# DSPIC33FJ12MC201 register map
Vendor: Microchip
Registers are 16-bit, read-write, reset 0x0 unless marked. A register's access mark holds for its fields unless they carry their own. Addresses are absolute, and some are shared; only a register's first bit layout is shown; [hi:lo] are bit positions; {n}, {i} and the like mark numbered series; 'fields as' and 'values as' point back to an identical list.

## SFR
{0x0+2i} WREG{i} (i=0..14)
0x1E WREG15 reset 0x800
0x20 SPLIM
0x22 ACCAL reset not defined — (power-on value xxxxxxxxxxxxxxxx)
0x24 ACCAH reset not defined — (power-on value xxxxxxxxxxxxxxxx)
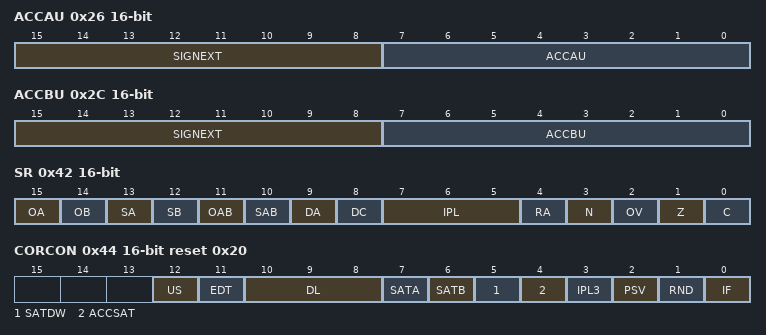
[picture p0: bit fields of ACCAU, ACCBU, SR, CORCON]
0x26 ACCAU reset not defined — (power-on value 00000000xxxxxxxx)
  [15:8] SIGNEXT ro, [7:0] ACCAU
0x28 ACCBL reset not defined — (power-on value xxxxxxxxxxxxxxxx)
0x2A ACCBH reset not defined — (power-on value xxxxxxxxxxxxxxxx)
0x2C ACCBU reset not defined — (power-on value 00000000xxxxxxxx)
  [15:8] SIGNEXT ro, [7:0] ACCBU
0x2E PCL ro
0x30 PCH ro
  [7:0] PCH
0x32 TBLPAG
  [7:0] TBLPAG
0x34 PSVPAG
  [7:0] PSVPAG
0x36 RCOUNT reset not defined — (power-on value --xxxxxxxxxxxxxx)
  [13:0] RCOUNT
0x38 DCOUNT reset not defined — (power-on value --xxxxxxxxxxxxxx)
  [13:0] DCOUNT
0x3A DOSTARTL reset not defined — (power-on value xxxxxxxxxxxxxxx0)
0x3C DOSTARTH reset not defined — (power-on value ----------xxxxxx)
  [5:0] DOSTARTH
0x3E DOENDL reset not defined — (power-on value xxxxxxxxxxxxxxx0)
0x40 DOENDH reset not defined — (power-on value ----------xxxxxx)
  [5:0] DOENDH
0x42 SR
  [15] OA ro
  [14] OB ro
  [13] SA — (can only be cleared)
  [12] SB — (can only be cleared)
  [11] OAB ro
  [10] SAB — (can only be cleared)
  [9] DA ro
  [8] DC
  [7:5] IPL
  [4] RA ro
  [3] N
  [2] OV
  [1] Z
  [0] C
0x44 CORCON reset 0x20
  [12] US
  [11] EDT wo
  [10:8] DL ro
  [7] SATA
  [6] SATB
  [5] SATDW
  [4] ACCSAT
  [3] IPL3 — (can only be cleared)
  [2] PSV
  [1] RND
  [0] IF
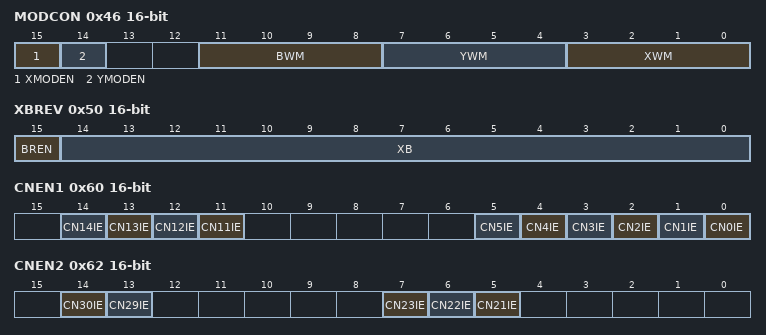
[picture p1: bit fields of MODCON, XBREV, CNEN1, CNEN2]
0x46 MODCON
  [15] XMODEN, [14] YMODEN, [11:8] BWM, [7:4] YWM, [3:0] XWM
0x48 XMODSRT reset not defined — (power-on value xxxxxxxxxxxxxxx0)
  [15:0] XS
0x4A XMODEND reset not defined — (power-on value xxxxxxxxxxxxxxx1)
  [15:0] XE
0x4C YMODSRT reset not defined — (power-on value xxxxxxxxxxxxxxx0)
  [15:0] YS
0x4E YMODEND reset not defined — (power-on value xxxxxxxxxxxxxxx1)
  [15:0] YE
0x50 XBREV reset not defined — (power-on value 0xxxxxxxxxxxxxxx)
  [15] BREN, [14:0] XB
0x52 DISICNT reset not defined — (power-on value --xxxxxxxxxxxxxx)
  [13:0] DISICNT
0x60 CNEN1
  [n] CN{n}IE (n=11..14), [n] CN{n}IE (n=0..5)
0x62 CNEN2
  [14] CN30IE, [13] CN29IE, [7] CN23IE, [6] CN22IE, [5] CN21IE
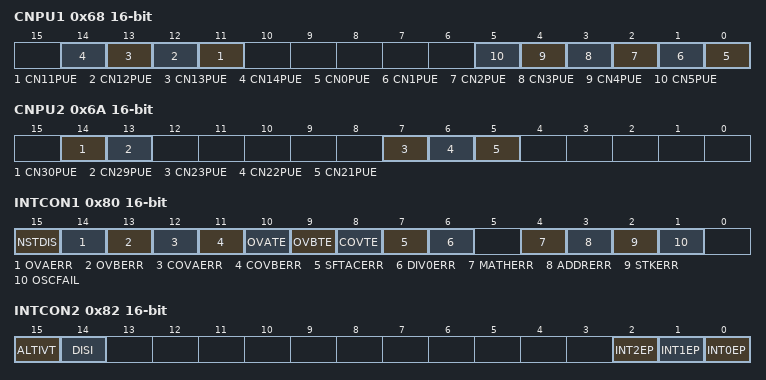
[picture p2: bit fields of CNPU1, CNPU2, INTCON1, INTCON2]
0x68 CNPU1
  [n] CN{n}PUE (n=11..14), [n] CN{n}PUE (n=0..5)
0x6A CNPU2
  [14] CN30PUE, [13] CN29PUE, [7] CN23PUE, [6] CN22PUE, [5] CN21PUE
0x80 INTCON1
  [15] NSTDIS, [14] OVAERR ro, [13] OVBERR ro, [12] COVAERR ro, [11] COVBERR ro, [10] OVATE, [9] OVBTE, [8] COVTE, [7] SFTACERR ro, [6] DIV0ERR ro, [4] MATHERR, [3] ADDRERR, [2] STKERR, [1] OSCFAIL
0x82 INTCON2
  [15] ALTIVT, [14] DISI ro, [2] INT2EP, [1] INT1EP, [0] INT0EP
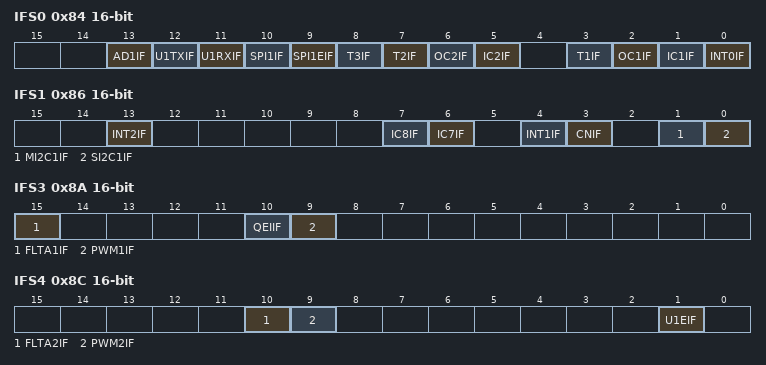
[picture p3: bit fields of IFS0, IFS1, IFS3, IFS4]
0x84 IFS0
  [13] AD1IF, [12] U1TXIF, [11] U1RXIF, [10] SPI1IF, [9] SPI1EIF, [8] T3IF, [7] T2IF, [6] OC2IF, [5] IC2IF, [3] T1IF, [2] OC1IF, [1] IC1IF, [0] INT0IF
0x86 IFS1
  [13] INT2IF, [7] IC8IF, [6] IC7IF, [4] INT1IF, [3] CNIF, [1] MI2C1IF, [0] SI2C1IF
0x8A IFS3
  [15] FLTA1IF, [10] QEIIF, [9] PWM1IF
0x8C IFS4
  [10] FLTA2IF, [9] PWM2IF, [1] U1EIF
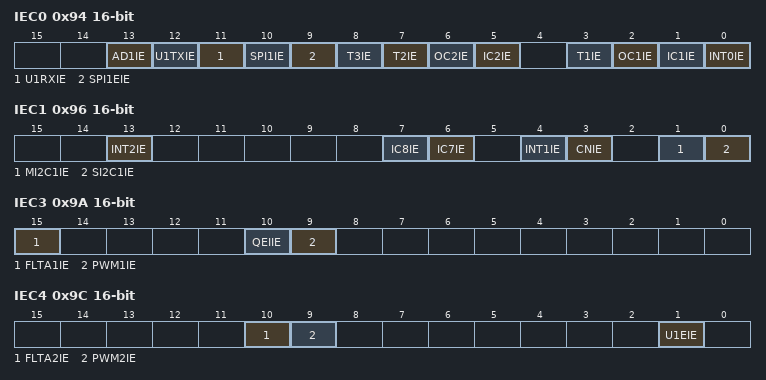
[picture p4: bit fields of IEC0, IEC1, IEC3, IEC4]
0x94 IEC0
  [13] AD1IE, [12] U1TXIE, [11] U1RXIE, [10] SPI1IE, [9] SPI1EIE, [8] T3IE, [7] T2IE, [6] OC2IE, [5] IC2IE, [3] T1IE, [2] OC1IE, [1] IC1IE, [0] INT0IE
0x96 IEC1
  [13] INT2IE, [7] IC8IE, [6] IC7IE, [4] INT1IE, [3] CNIE, [1] MI2C1IE, [0] SI2C1IE
0x9A IEC3
  [15] FLTA1IE, [10] QEIIE, [9] PWM1IE
0x9C IEC4
  [10] FLTA2IE, [9] PWM2IE, [1] U1EIE
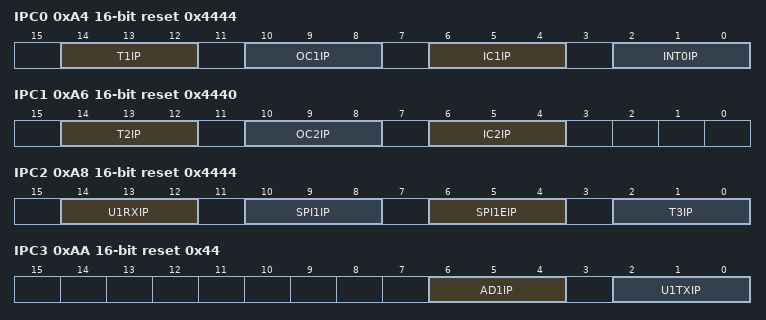
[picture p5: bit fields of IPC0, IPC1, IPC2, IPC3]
0xA4 IPC0 reset 0x4444
  [14:12] T1IP, [10:8] OC1IP, [6:4] IC1IP, [2:0] INT0IP
0xA6 IPC1 reset 0x4440
  [14:12] T2IP, [10:8] OC2IP, [6:4] IC2IP
0xA8 IPC2 reset 0x4444
  [14:12] U1RXIP, [10:8] SPI1IP, [6:4] SPI1EIP, [2:0] T3IP
0xAA IPC3 reset 0x44
  [6:4] AD1IP, [2:0] U1TXIP
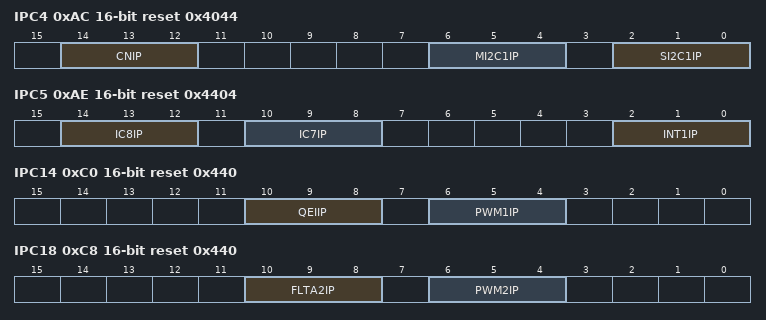
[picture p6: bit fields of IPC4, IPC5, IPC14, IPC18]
0xAC IPC4 reset 0x4044
  [14:12] CNIP, [6:4] MI2C1IP, [2:0] SI2C1IP
0xAE IPC5 reset 0x4404
  [14:12] IC8IP, [10:8] IC7IP, [2:0] INT1IP
0xB2 IPC7 reset 0x40
  [6:4] INT2IP
0xC0 IPC14 reset 0x440
  [10:8] QEIIP, [6:4] PWM1IP
0xC2 IPC15 reset 0x4000
  [14:12] FLTA1IP
0xC4 IPC16 reset 0x40
  [6:4] U1EIP
0xC8 IPC18 reset 0x440
  [10:8] FLTA2IP, [6:4] PWM2IP
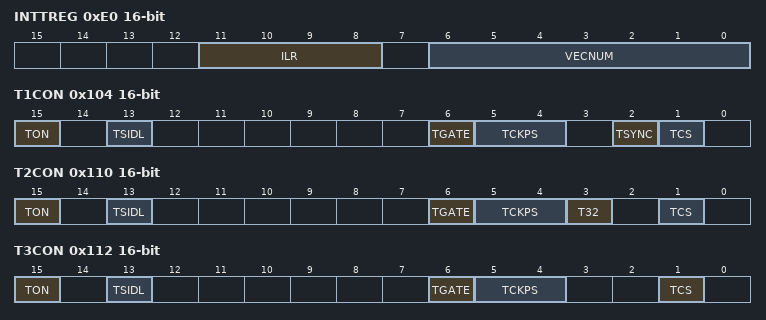
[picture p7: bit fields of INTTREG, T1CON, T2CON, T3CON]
0xE0 INTTREG
  [11:8] ILR ro, [6:0] VECNUM
0x100 TMR1 reset not defined — (power-on value xxxxxxxxxxxxxxxx)
0x102 PR1 reset 0xFFFF
0x104 T1CON
  [15] TON, [13] TSIDL, [6] TGATE, [5:4] TCKPS, [2] TSYNC, [1] TCS
0x106 TMR2 reset not defined — (power-on value xxxxxxxxxxxxxxxx)
0x108 TMR3HLD reset not defined — (power-on value xxxxxxxxxxxxxxxx)
0x10A TMR3 reset not defined — (power-on value xxxxxxxxxxxxxxxx)
0x10C PR2 reset 0xFFFF
0x10E PR3 reset 0xFFFF
0x110 T2CON
  [15] TON, [13] TSIDL, [6] TGATE, [5:4] TCKPS, [3] T32, [1] TCS
0x112 T3CON
  [15] TON, [13] TSIDL, [6] TGATE, [5:4] TCKPS, [1] TCS
0x140 IC1BUF ro reset not defined — (power-on value xxxxxxxxxxxxxxxx)
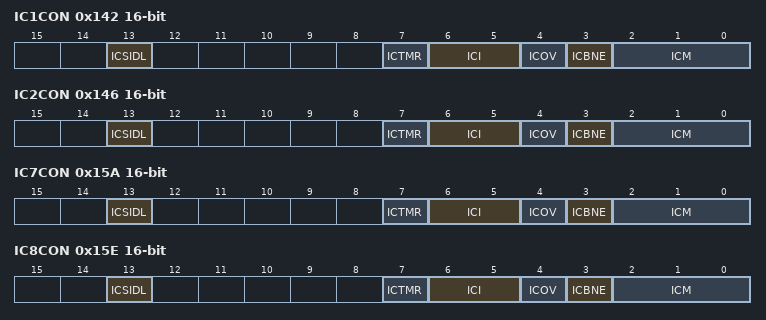
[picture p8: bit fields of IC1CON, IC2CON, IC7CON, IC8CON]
0x142 IC1CON
  [13] ICSIDL, [7] ICTMR, [6:5] ICI, [4] ICOV ro, [3] ICBNE ro, [2:0] ICM
0x144 IC2BUF ro reset not defined — (power-on value xxxxxxxxxxxxxxxx)
0x146 IC2CON
  fields as IC1CON
0x158 IC7BUF ro reset not defined — (power-on value xxxxxxxxxxxxxxxx)
0x15A IC7CON
  fields as IC1CON
0x15C IC8BUF ro reset not defined — (power-on value xxxxxxxxxxxxxxxx)
0x15E IC8CON
  fields as IC1CON
0x180 OC1RS reset not defined — (power-on value xxxxxxxxxxxxxxxx)
0x182 OC1R reset not defined — (power-on value xxxxxxxxxxxxxxxx)
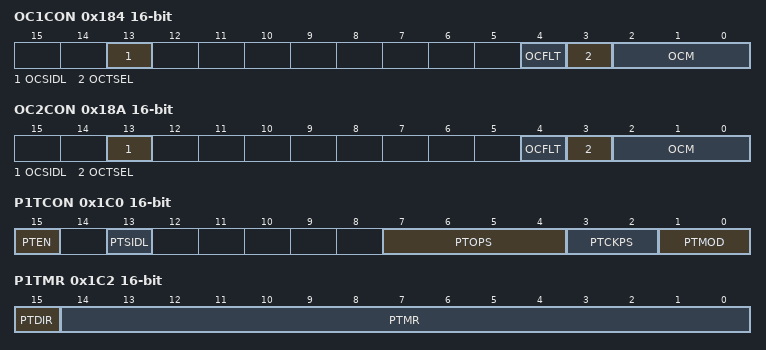
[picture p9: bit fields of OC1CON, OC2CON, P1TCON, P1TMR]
0x184 OC1CON
  [13] OCSIDL, [4] OCFLT ro, [3] OCTSEL, [2:0] OCM
0x186 OC2RS reset not defined — (power-on value xxxxxxxxxxxxxxxx)
0x188 OC2R reset not defined — (power-on value xxxxxxxxxxxxxxxx)
0x18A OC2CON
  [13] OCSIDL, [4] OCFLT ro, [3] OCTSEL, [2:0] OCM
0x1C0 P1TCON reset not defined — (power-on value 0-0-----xxxxxxxx)
  [15] PTEN, [13] PTSIDL, [7:4] PTOPS, [3:2] PTCKPS, [1:0] PTMOD
0x1C2 P1TMR
  [15] PTDIR ro, [14:0] PTMR
0x1C4 P1TPER
  [14:0] PTPER
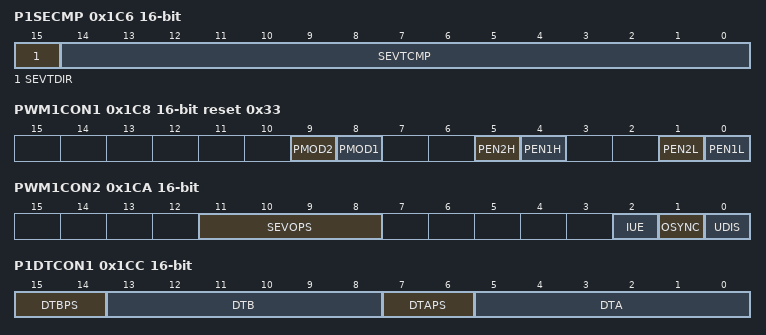
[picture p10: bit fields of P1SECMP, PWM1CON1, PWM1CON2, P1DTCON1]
0x1C6 P1SECMP
  [15] SEVTDIR, [14:0] SEVTCMP
0x1C8 PWM1CON1 reset 0x33
  [9] PMOD2, [8] PMOD1, [5] PEN2H, [4] PEN1H, [1] PEN2L, [0] PEN1L
0x1CA PWM1CON2
  [11:8] SEVOPS, [2] IUE, [1] OSYNC, [0] UDIS
0x1CC P1DTCON1
  [15:14] DTBPS, [13:8] DTB, [7:6] DTAPS, [5:0] DTA
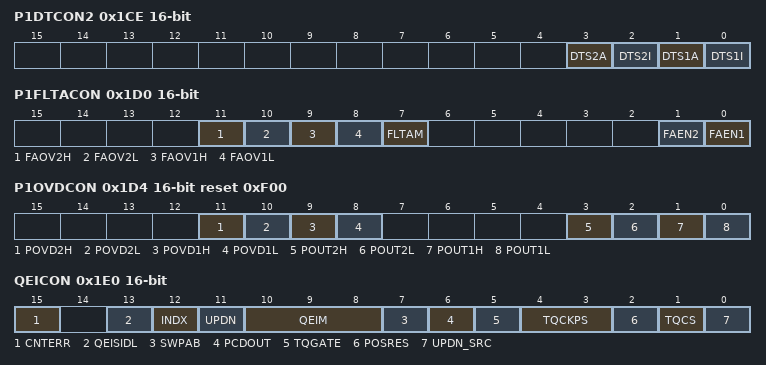
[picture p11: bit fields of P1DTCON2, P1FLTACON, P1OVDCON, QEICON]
0x1CE P1DTCON2
  [3] DTS2A, [2] DTS2I, [1] DTS1A, [0] DTS1I
0x1D0 P1FLTACON
  [11] FAOV2H, [10] FAOV2L, [9] FAOV1H, [8] FAOV1L, [7] FLTAM, [1] FAEN2, [0] FAEN1
0x1D4 P1OVDCON reset 0xF00
  [11] POVD2H, [10] POVD2L, [9] POVD1H, [8] POVD1L, [3] POUT2H, [2] POUT2L, [1] POUT1H, [0] POUT1L
0x1D6 P1DC1
  [15:0] PWMDC1
0x1D8 P1DC2
  [15:0] PWMDC2
0x1E0 QEICON
  [15] CNTERR, [13] QEISIDL, [12] INDX ro, [11] UPDN, [10:8] QEIM, [7] SWPAB, [6] PCDOUT, [5] TQGATE, [4:3] TQCKPS, [2] POSRES, [1] TQCS, [0] UPDN_SRC
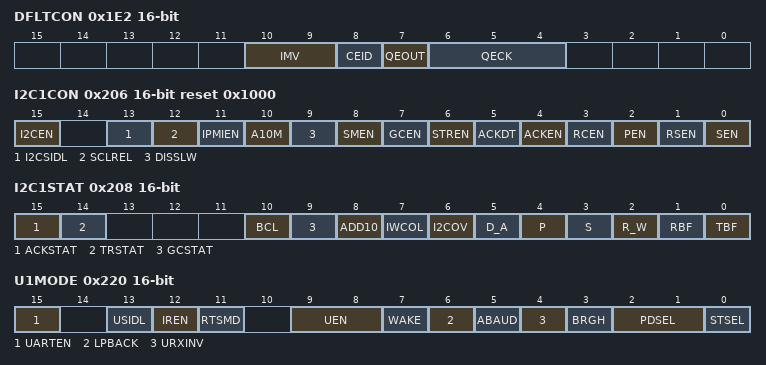
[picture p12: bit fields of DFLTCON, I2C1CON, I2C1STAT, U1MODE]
0x1E2 DFLTCON reset not defined — (power-on value -----xx00xxx----)
  [10:9] IMV, [8] CEID, [7] QEOUT, [6:4] QECK
0x1E4 POSCNT
0x1E6 MAXCNT reset 0xFFFF
0x200 I2C1RCV ro
  [7:0] I2C1RCV
0x202 I2C1TRN wo reset 0xFF
  [7:0] I2C1TRN
0x204 I2C1BRG
  [8:0] I2C1BRG
0x206 I2C1CON reset 0x1000
  [15] I2CEN, [13] I2CSIDL, [12] SCLREL, [11] IPMIEN, [10] A10M, [9] DISSLW, [8] SMEN, [7] GCEN, [6] STREN, [5] ACKDT, [4] ACKEN, [3] RCEN, [2] PEN, [1] RSEN, [0] SEN
0x208 I2C1STAT
  [15] ACKSTAT ro
  [14] TRSTAT ro
  [10] BCL ro
  [9] GCSTAT ro
  [8] ADD10 ro
  [7] IWCOL — (can only be cleared)
  [6] I2COV — (can only be cleared)
  [5] D_A ro
  [4] P — (can only be cleared)
  [3] S — (can only be cleared)
  [2] R_W ro
  [1] RBF ro
  [0] TBF ro
0x20A I2C1ADD
  [9:0] I2C1ADD
0x20C I2C1MSK
  [9:0] AMSK
0x220 U1MODE
  [15] UARTEN, [13] USIDL, [12] IREN, [11] RTSMD, [9:8] UEN, [7] WAKE, [6] LPBACK, [5] ABAUD, [4] URXINV, [3] BRGH, [2:1] PDSEL, [0] STSEL
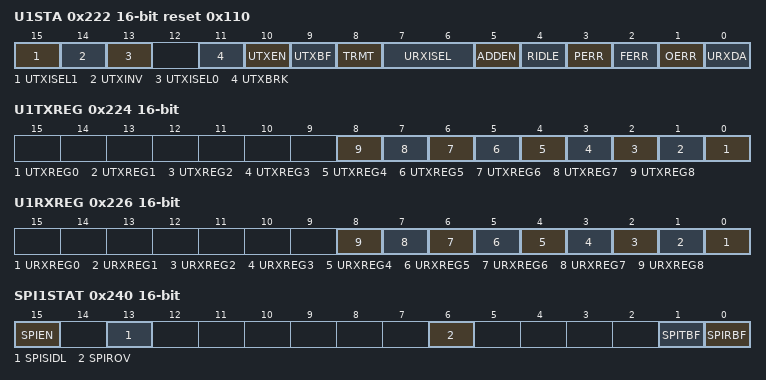
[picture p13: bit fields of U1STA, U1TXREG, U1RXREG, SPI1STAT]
0x222 U1STA reset 0x110
  [15] UTXISEL1
  [14] UTXINV
  [13] UTXISEL0
  [11] UTXBRK
  [10] UTXEN
  [9] UTXBF ro
  [8] TRMT ro
  [7:6] URXISEL
  [5] ADDEN
  [4] RIDLE ro
  [3] PERR ro
  [2] FERR ro
  [1] OERR — (can only be cleared)
  [0] URXDA ro
0x224 U1TXREG reset not defined — (power-on value -------xxxxxxxxx)
  [n] UTXREG{n} (n=0..8)
0x226 U1RXREG reset not defined — (power-on value -------xxxxxxxxx)
  [n] URXREG{n} (n=0..8)
0x228 U1BRG
  [15:0] BRG
0x240 SPI1STAT
  [15] SPIEN
  [13] SPISIDL
  [6] SPIROV — (can only be cleared)
  [1] SPITBF
  [0] SPIRBF
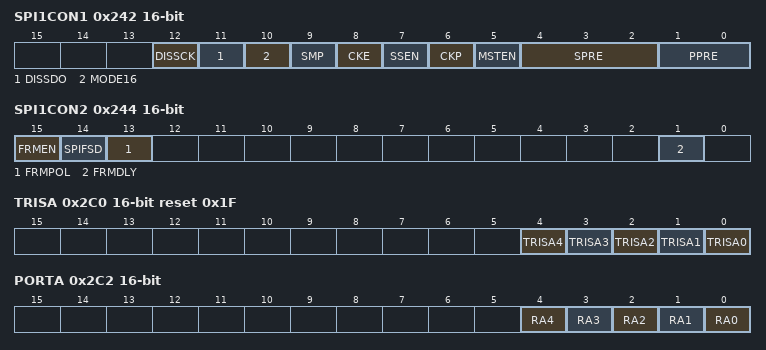
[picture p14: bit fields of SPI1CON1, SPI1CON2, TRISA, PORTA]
0x242 SPI1CON1
  [12] DISSCK, [11] DISSDO, [10] MODE16, [9] SMP, [8] CKE, [7] SSEN, [6] CKP, [5] MSTEN, [4:2] SPRE, [1:0] PPRE
0x244 SPI1CON2
  [15] FRMEN, [14] SPIFSD, [13] FRMPOL, [1] FRMDLY
0x248 SPI1BUF
0x2C0 TRISA reset 0x1F
  [n] TRISA{n} (n=0..4)
0x2C2 PORTA reset not defined — (power-on value -----------xxxxx)
  [n] RA{n} (n=0..4)
0x2C4 LATA
  [n] LATA{n} (n=0..4)
0x2C6 ODCA
  [n] ODCA{n} (n=0..4)
0x2C8 TRISB reset 0xF393
  [n] TRISB{n} (n=12..15), [9] TRISB9, [8] TRISB8, [7] TRISB7, [4] TRISB4, [1] TRISB1, [0] TRISB0
0x2CA PORTB reset not defined — (power-on value xxxx--xxx--x--xx)
  [n] RB{n} (n=12..15), [9] RB9, [8] RB8, [7] RB7, [4] RB4, [1] RB1, [0] RB0
0x2CC LATB
  [n] LATB{n} (n=12..15), [9] LATB9, [8] LATB8, [7] LATB7, [4] LATB4, [1] LATB1, [0] LATB0
0x2CE ODCB
  [n] ODCB{n} (n=12..15), [9] ODCB9, [8] ODCB8, [7] ODCB7, [4] ODCB4, [1] ODCB1, [0] ODCB0
{0x300+2i} ADC1BUF{i} ro reset not defined (i=0..9) — (power-on value xxxxxxxxxxxxxxxx)
0x314 ADC1BUFA ro reset not defined — (power-on value xxxxxxxxxxxxxxxx)
  [15:0] ADC1BUF10
0x316 ADC1BUFB ro reset not defined — (power-on value xxxxxxxxxxxxxxxx)
  [15:0] ADC1BUF11
0x318 ADC1BUFC ro reset not defined — (power-on value xxxxxxxxxxxxxxxx)
  [15:0] ADC1BUF12
0x31A ADC1BUFD ro reset not defined — (power-on value xxxxxxxxxxxxxxxx)
  [15:0] ADC1BUF13
0x31C ADC1BUFE ro reset not defined — (power-on value xxxxxxxxxxxxxxxx)
  [15:0] ADC1BUF14
0x31E ADC1BUFF ro reset not defined — (power-on value xxxxxxxxxxxxxxxx)
  [15:0] ADC1BUF15
0x320 AD1CON1 reset not defined — (power-on value 0-0--x00000--000)
  [15] ADON
  [13] ADSIDL
  [10] AD12B
  [9:8] FORM
  [7:5] SSRC
  [3] SIMSAM
  [2] ASAM
  [1] SAMP
  [0] DONE — (can only be cleared)
0x322 AD1CON2
  [15:13] VCFG, [10] CSCNA, [9:8] CHPS, [7] BUFS ro, [5:2] SMPI, [1] BUFM, [0] ALTS
0x324 AD1CON3 reset not defined — (power-on value 0--00000xxxxxxxx)
  [15] ADRC, [12:8] SAMC, [7:0] ADCS
0x326 AD1CHS123
  [10:9] CH123NB, [8] CH123SB, [2:1] CH123NA, [0] CH123SA
0x328 AD1CHS0 reset not defined — (power-on value 0--xxxxx0--xxxxx)
  [15] CH0NB, [12:8] CH0SB, [7] CH0NA, [4:0] CH0SA
0x32C AD1PCFGL reset not defined — (power-on value ------------xxxx)
  [n] PCFG{n} (n=0..3)
0x330 AD1CSSL reset not defined — (power-on value ------------xxxx)
  [n] CSS{n} (n=0..3)
0x5C0 P2TCON
  [15] PTEN, [13] PTSIDL, [7:4] PTOPS, [3:2] PTCKPS, [1:0] PTMOD
0x5C2 P2TMR
  [15] PTDIR ro, [14:0] PTMR
0x5C4 P2TPER
  [14:0] PTPER
0x5C6 P2SECMP
  [15] SEVTDIR, [14:0] SEVTCMP
0x5C8 PWM2CON1 reset 0x11
  [8] PMOD1, [4] PEN1H, [0] PEN1L
0x5CA PWM2CON2 reset not defined — (power-on value ----xxxx-----000)
  [11:8] SEVOPS, [2] IUE, [1] OSYNC, [0] UDIS
0x5CC P2DTCON1
  [15:14] DTBPS, [13:8] DTB, [7:6] DTAPS, [5:0] DTA
0x5CE P2DTCON2
  [1] DTS1A, [0] DTS1I
0x5D0 P2FLTACON
  [9] FAOV1H, [8] FAOV1L, [7] FLTAM, [0] FAEN1
0x5D4 P2OVDCON reset 0x300
  [9] POVD1H, [8] POVD1L, [1] POUT1H, [0] POUT1L
0x5D6 P2DC1
  [15:0] PWMDC1
0x680 RPINR0 reset 0x1F00
  [12:8] INT1R
0x682 RPINR1 reset 0x1F
  [4:0] INT2R
0x686 RPINR3 reset 0x1F1F
  [12:8] T3CKR, [4:0] T2CKR
0x68E RPINR7 reset 0x1F1F
  [12:8] IC2R, [4:0] IC1R
0x694 RPINR10 reset 0x1F1F
  [12:8] IC8R, [4:0] IC7R
0x696 RPINR11 reset 0x1F
  [4:0] OCFAR
0x698 RPINR12 reset 0x1F
  [4:0] FLTA1R
0x69A RPINR13 reset 0x1F
  [4:0] FLTA2R
0x69C RPINR14 reset 0x1F1F
  [12:8] QEB1R, [4:0] QEA1R
0x69E RPINR15 reset 0x1F
  [4:0] INDX1R
0x6A4 RPINR18 reset 0x1F1F
  [12:8] U1CTSR, [4:0] U1RXR
0x6A8 RPINR20 reset 0x1F1F
  [12:8] SCK1R, [4:0] SDI1R
0x6AA RPINR21 reset 0x1F
  [4:0] SS1R
0x6C0 RPOR0
  [12:8] RP1R, [4:0] RP0R
0x6C4 RPOR2
  [4:0] RP4R
0x6C6 RPOR3
  [12:8] RP7R
0x6C8 RPOR4
  [12:8] RP9R, [4:0] RP8R
0x6CC RPOR6
  [12:8] RP13R, [4:0] RP12R
0x6CE RPOR7
  [12:8] RP15R, [4:0] RP14R
0x740 RCON reset 0x3
  [15] TRAPR, [14] IOPUWR, [9] CM, [8] VREGS, [7] EXTR, [6] SWR, [5] SWDTEN, [4] WDTO, [3] SLEEP, [2] IDLE, [1] BOR, [0] POR
0x742 OSCCON reset not defined — (power-on value -000-yyy0---0000)
  [14:12] COSC ro, [10:8] NOSC, [7] CLKLOCK, [6] IOLOCK, [5] LOCK ro, [3] CF ro, [1] LPOSCEN, [0] OSWEN
0x744 CLKDIV reset 0x3040
  [15] ROI, [14:12] DOZE, [11] DOZEN, [10:8] FRCDIV, [7:6] PLLPOST, [4:0] PLLPRE
0x746 PLLFBD reset 0x30
  [8:0] PLLDIV
0x748 OSCTUN
  [5:0] TUN
0x760 NVMCON
  [15] WR — (can only be set)
  [14] WREN
  [13] WRERR
  [6] ERASE
  [3:0] NVMOP
0x766 NVMKEY wo
  [7:0] NVMKEY
0x770 PMD1
  [13] T3MD, [12] T2MD, [11] T1MD, [10] QEIMD, [9] PWM1MD, [7] I2C1MD, [5] U1MD, [3] SPI1MD, [0] AD1MD
0x772 PMD2 reset not defined — (power-on value xx----00------00)
  [15] IC8MD, [14] IC7MD, [9] IC2MD, [8] IC1MD, [1] OC2MD, [0] OC1MD
0x774 PMD3
  [4] PWM2MD
